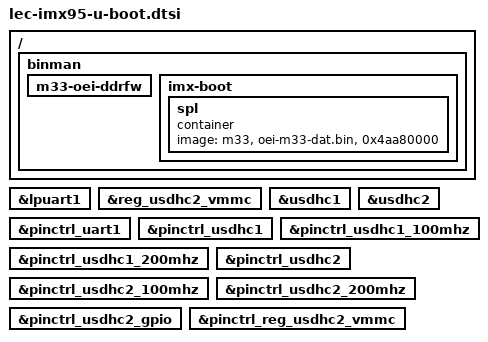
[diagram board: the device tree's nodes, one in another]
// SPDX-License-Identifier: GPL-2.0+


/*
 * ADLINK LEC-iMX95 U-Boot specific configuration
 */


/ {
	binman {
		m33-oei-ddrfw {
		};

		imx-boot {
			spl {
				container;
				image = "m33", "oei-m33-dat.bin", "0x4aa80000";
			};
		};
	};

};

#include "imx95-u-boot.dtsi"

&lpuart1 {
	bootph-pre-ram;
};

&reg_usdhc2_vmmc {
	bootph-pre-ram;
};

&usdhc1 {
	bootph-pre-ram;
};

&usdhc2 {
	bootph-pre-ram;
};

&pinctrl_uart1 {
	bootph-pre-ram;
};

&pinctrl_usdhc1 {
	bootph-pre-ram;
};

&pinctrl_usdhc1_100mhz {
	bootph-pre-ram;
};

&pinctrl_usdhc1_200mhz {
	bootph-pre-ram;
};

&pinctrl_usdhc2 {
	bootph-pre-ram;
};

&pinctrl_usdhc2_100mhz {
	bootph-pre-ram;
};

&pinctrl_usdhc2_200mhz {
	bootph-pre-ram;
};

&pinctrl_usdhc2_gpio {
	bootph-pre-ram;
};

&pinctrl_reg_usdhc2_vmmc {
	bootph-pre-ram;
};
